VERSION ""

NS_ :

BS_:

BU_:

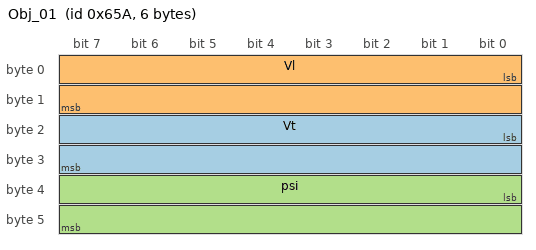
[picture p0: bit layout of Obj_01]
BO_ 1626 Obj_01: 6 Vector__XXX
 SG_ Vt : 16|16@1- (0.01,0) [-327.68|327.67] "m/s" Vector__XXX
 SG_ Vl : 0|16@1- (0.01,0) [-327.68|327.67] "m/s" Vector__XXX
 SG_ psi : 32|16@1- (0.01,0) [-327.68|327.67] "deg" Vector__XXX

BO_ 1625 Obj_00: 8 Vector__XXX

BA_DEF_  "BusType" STRING ;
BA_DEF_DEF_  "BusType" "";
BA_ "BusType" "CAN";
